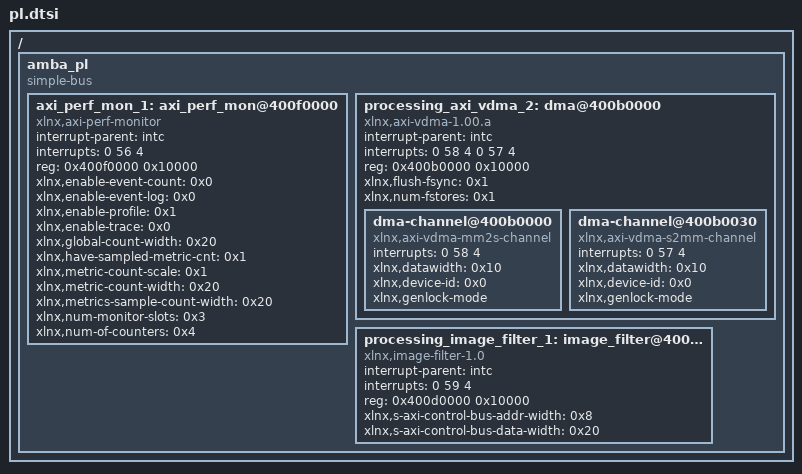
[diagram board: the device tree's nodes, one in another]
/*
 * CAUTION: This file is automatically generated by Xilinx.
 * Version:  
 * Today is: Mon Dec  5 22:21:56 2016
*/


/ {
	amba_pl: amba_pl {
		#address-cells = <1>;
		#size-cells = <1>;
		compatible = "simple-bus";
		ranges ;
		axi_perf_mon_1: axi_perf_mon@400f0000 {
			compatible = "xlnx,axi-perf-monitor";
			interrupt-parent = <&intc>;
			interrupts = <0 56 4>;
			reg = <0x400f0000 0x10000>;
			xlnx,enable-event-count = <0x0>;
			xlnx,enable-event-log = <0x0>;
			xlnx,enable-profile = <0x1>;
			xlnx,enable-trace = <0x0>;
			xlnx,global-count-width = <0x20>;
			xlnx,have-sampled-metric-cnt = <0x1>;
			xlnx,metric-count-scale = <0x1>;
			xlnx,metric-count-width = <0x20>;
			xlnx,metrics-sample-count-width = <0x20>;
			xlnx,num-monitor-slots = <0x3>;
			xlnx,num-of-counters = <0x4>;
		};
		processing_axi_vdma_2: dma@400b0000 {
			#dma-cells = <1>;
			compatible = "xlnx,axi-vdma-1.00.a";
			interrupt-parent = <&intc>;
			interrupts = <0 58 4 0 57 4>;
			reg = <0x400b0000 0x10000>;
			xlnx,flush-fsync = <0x1>;
			xlnx,num-fstores = <0x1>;
			dma-channel@400b0000 {
				compatible = "xlnx,axi-vdma-mm2s-channel";
				interrupts = <0 58 4>;
				xlnx,datawidth = <0x10>;
				xlnx,device-id = <0x0>;
				xlnx,genlock-mode ;
			};
			dma-channel@400b0030 {
				compatible = "xlnx,axi-vdma-s2mm-channel";
				interrupts = <0 57 4>;
				xlnx,datawidth = <0x10>;
				xlnx,device-id = <0x0>;
				xlnx,genlock-mode ;
			};
		};
		processing_image_filter_1: image_filter@400d0000 {
			compatible = "xlnx,image-filter-1.0";
			interrupt-parent = <&intc>;
			interrupts = <0 59 4>;
			reg = <0x400d0000 0x10000>;
			xlnx,s-axi-control-bus-addr-width = <0x8>;
			xlnx,s-axi-control-bus-data-width = <0x20>;
		};
	};
};
